VERSION ""

NS_ :

BS_:

BU_: FrontBoard BackBoard Kvaser SteeringWheel TCU GPS ACULV Bamocar PDM

BO_ 3221225472 VECTOR__INDEPENDENT_SIG_MSG: 0 Vector__XXX
 SG_ NewSignal_0021 : 0|8@1+ (1,0) [0|0] "" Vector__XXX
 SG_ NewSignal_0024 : 40|8@1+ (1,0) [0|0] "" Vector__XXX
 SG_ IsolationMonitoring : 32|8@1+ (1,0) [0|0] "" Vector__XXX
 SG_ NewSignal_0027 : 0|8@1+ (1,0) [0|0] "" Vector__XXX
 SG_ NewSignal_0029 : 8|8@1+ (1,0) [0|0] "" Vector__XXX
 SG_ Freq1 : 0|32@1- (1,0) [0|0] ""  Kvaser,SteeringWheel
 SG_ Freq2 : 32|32@1- (1,0) [0|0] ""  Kvaser,SteeringWheel

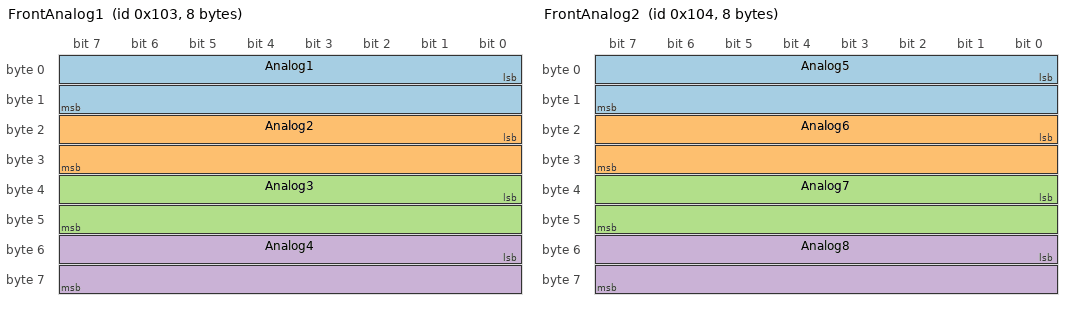
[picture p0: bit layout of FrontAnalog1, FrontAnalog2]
BO_ 259 FrontAnalog1: 8 FrontBoard
 SG_ Analog1 : 0|16@1+ (1,0) [0|0] ""  FrontBoard,Kvaser,SteeringWheel
 SG_ Analog2 : 16|16@1+ (1,0) [0|0] ""  FrontBoard,Kvaser,SteeringWheel
 SG_ Analog3 : 32|16@1+ (1,0) [0|0] ""  FrontBoard,Kvaser,SteeringWheel
 SG_ Analog4 : 48|16@1+ (1,0) [0|0] ""  FrontBoard,Kvaser,SteeringWheel

BO_ 260 FrontAnalog2: 8 FrontBoard
 SG_ Analog5 : 0|16@1+ (1,0) [0|0] ""  FrontBoard,Kvaser,SteeringWheel
 SG_ Analog6 : 16|16@1+ (1,0) [0|0] ""  FrontBoard,Kvaser,SteeringWheel
 SG_ Analog7 : 32|16@1+ (1,0) [0|0] ""  FrontBoard,Kvaser,SteeringWheel
 SG_ Analog8 : 48|16@1+ (1,0) [0|0] ""  FrontBoard,Kvaser,SteeringWheel

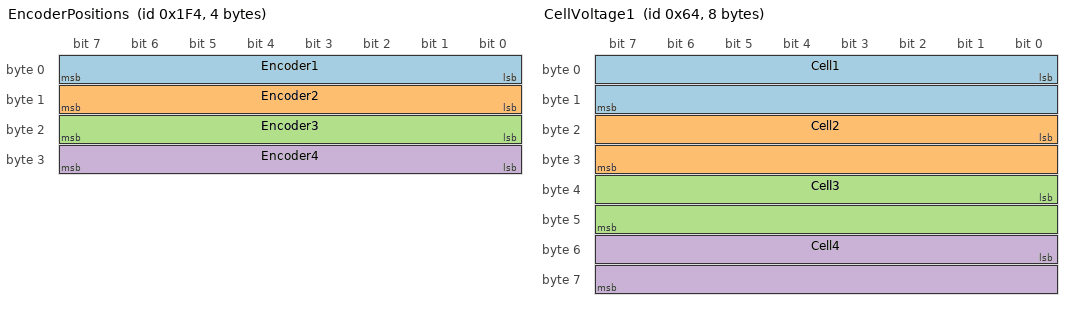
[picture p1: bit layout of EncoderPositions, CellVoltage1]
BO_ 500 EncoderPositions: 4 SteeringWheel
 SG_ Encoder1 : 0|8@1+ (1,0) [0|0] ""  Kvaser
 SG_ Encoder2 : 8|8@1+ (1,0) [0|0] ""  Kvaser
 SG_ Encoder3 : 16|8@1+ (1,0) [0|0] ""  Kvaser
 SG_ Encoder4 : 24|8@1+ (1,0) [0|0] ""  Kvaser

BO_ 1550 FrontStrainGauges1: 8 FrontBoard
 SG_ Gauge1 : 0|24@1+ (1,0) [0|0] ""  Kvaser
 SG_ Gauge2 : 24|24@1+ (1,0) [0|0] ""  Kvaser

BO_ 1551 FrontStrainGauges2: 8 FrontBoard
 SG_ Gauge3 : 0|24@1+ (1,0) [0|0] ""  Kvaser
 SG_ Gauge4 : 24|24@1+ (1,0) [0|0] ""  Kvaser

BO_ 1552 FrontStrainGauges3: 8 FrontBoard
 SG_ Gauge5 : 0|24@1+ (1,0) [0|0] ""  Kvaser
 SG_ Gauge6 : 24|24@1+ (1,0) [0|0] ""  Kvaser

BO_ 1553 FrontStrainGauges4: 8 FrontBoard
 SG_ Gauge7 : 0|24@1+ (1,0) [0|0] ""  Kvaser
 SG_ Gauge8 : 24|24@1+ (1,0) [0|0] ""  Kvaser

BO_ 1554 FrontStrainGauges5: 8 FrontBoard
 SG_ Gauge9 : 0|24@1+ (1,0) [0|0] ""  Kvaser
 SG_ Gauge10 : 24|24@1+ (1,0) [0|0] ""  Kvaser

BO_ 1555 FrontStrainGauges6: 8 FrontBoard
 SG_ Gauge11 : 0|24@1+ (1,0) [0|0] ""  Kvaser
 SG_ Gauge12 : 24|24@1+ (1,0) [0|0] ""  Kvaser

BO_ 1560 RearStrainGauges1: 8 BackBoard
 SG_ Gauge1 : 0|24@1+ (1,0) [0|0] ""  Kvaser
 SG_ Gauge2 : 24|24@1+ (1,0) [0|0] ""  Kvaser

BO_ 1561 RearStrainGauges2: 8 BackBoard
 SG_ Gauge3 : 0|24@1+ (1,0) [0|0] ""  Kvaser
 SG_ Gauge4 : 24|24@1+ (1,0) [0|0] ""  Kvaser

BO_ 1562 RearStrainGauges3: 8 BackBoard
 SG_ Gauge5 : 0|24@1+ (1,0) [0|0] ""  Kvaser
 SG_ Gauge6 : 24|24@1+ (1,0) [0|0] ""  Kvaser

BO_ 1563 RearStrainGauges4: 8 BackBoard
 SG_ Gauge7 : 0|24@1+ (1,0) [0|0] ""  Kvaser
 SG_ Gauge8 : 24|24@1+ (1,0) [0|0] ""  Kvaser

BO_ 1564 RearStrainGauges5: 8 BackBoard
 SG_ Gauge9 : 0|24@1+ (1,0) [0|0] ""  Kvaser
 SG_ Gauge10 : 24|24@1+ (1,0) [0|0] ""  Kvaser

BO_ 1565 RearStrainGauges6: 8 BackBoard
 SG_ Gauge11 : 0|24@1+ (1,0) [0|0] ""  Kvaser
 SG_ Gauge12 : 24|24@1+ (1,0) [0|0] ""  Kvaser

BO_ 80 GPSBestPos: 64 GPS
 SG_ Latitude : 0|64@1- (1,0) [0|0] ""  Kvaser,SteeringWheel
 SG_ Longitude : 64|64@1- (1,0) [0|0] ""  Kvaser,SteeringWheel
 SG_ Altitude : 128|64@1- (1,0) [0|0] ""  Kvaser,SteeringWheel
 SG_ stdLatitude : 192|64@1- (1,0) [0|0] ""  Kvaser,SteeringWheel
 SG_ stdLongitude : 256|64@1- (1,0) [0|0] ""  Kvaser,SteeringWheel
 SG_ stdAltitude : 320|64@1- (1,0) [0|0] ""  Kvaser,SteeringWheel
 SG_ gpsStatus : 384|8@1+ (1,0) [0|0] "" Vector__XXX

BO_ 513 BamocarRxData: 6 TCU
 SG_ REGID : 0|8@1- (1,0) [0|0] ""  Kvaser,SteeringWheel
 SG_ Byte1 : 8|8@1+ (1,0) [0|0] ""  Kvaser,SteeringWheel
 SG_ Byte2 : 16|8@1+ (1,0) [0|0] ""  Kvaser,SteeringWheel
 SG_ Byte3 : 24|8@1+ (1,0) [0|0] ""  Kvaser,SteeringWheel
 SG_ Byte4 : 32|8@1+ (1,0) [0|0] ""  Kvaser,SteeringWheel
 SG_ Byte5 : 40|8@1+ (1,0) [0|0] ""  Kvaser,SteeringWheel

BO_ 100 CellVoltage1: 8 ACULV
 SG_ Cell1 : 0|16@1+ (1,0) [0|0] ""  Kvaser,SteeringWheel
 SG_ Cell2 : 16|16@1+ (1,0) [0|0] ""  Kvaser,SteeringWheel
 SG_ Cell3 : 32|16@1+ (1,0) [0|0] ""  Kvaser,SteeringWheel
 SG_ Cell4 : 48|16@1+ (1,0) [0|0] ""  Kvaser,SteeringWheel

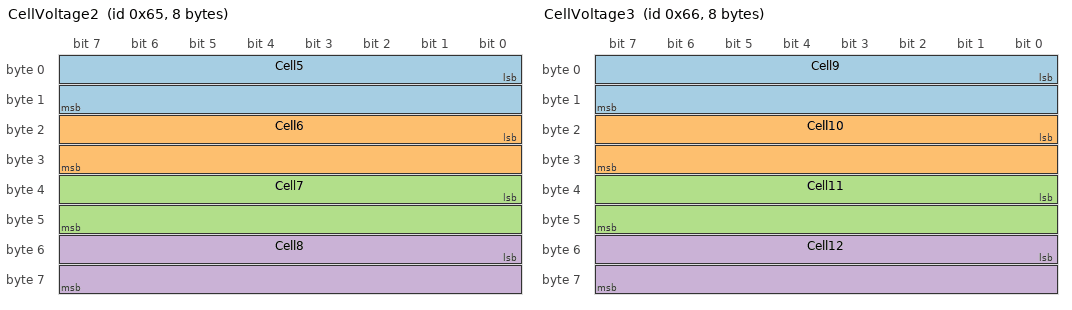
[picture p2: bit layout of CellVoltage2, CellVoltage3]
BO_ 101 CellVoltage2: 8 ACULV
 SG_ Cell5 : 0|16@1+ (1,0) [0|0] ""  Kvaser,SteeringWheel
 SG_ Cell6 : 16|16@1+ (1,0) [0|0] ""  Kvaser,SteeringWheel
 SG_ Cell7 : 32|16@1+ (1,0) [0|0] ""  Kvaser,SteeringWheel
 SG_ Cell8 : 48|16@1+ (1,0) [0|0] ""  Kvaser,SteeringWheel

BO_ 102 CellVoltage3: 8 ACULV
 SG_ Cell9 : 0|16@1+ (1,0) [0|0] ""  Kvaser,SteeringWheel
 SG_ Cell10 : 16|16@1+ (1,0) [0|0] ""  Kvaser,SteeringWheel
 SG_ Cell11 : 32|16@1+ (1,0) [0|0] ""  Kvaser,SteeringWheel
 SG_ Cell12 : 48|16@1+ (1,0) [0|0] ""  Kvaser,SteeringWheel

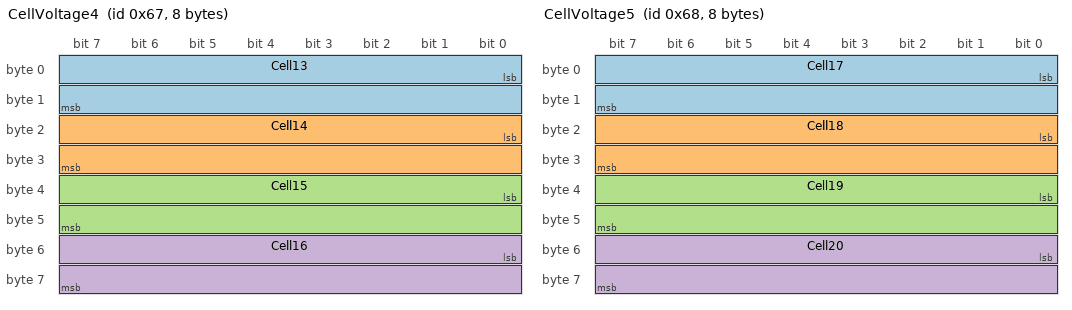
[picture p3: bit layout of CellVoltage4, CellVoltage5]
BO_ 103 CellVoltage4: 8 ACULV
 SG_ Cell13 : 0|16@1+ (1,0) [0|0] ""  Kvaser,SteeringWheel
 SG_ Cell14 : 16|16@1+ (1,0) [0|0] ""  Kvaser,SteeringWheel
 SG_ Cell15 : 32|16@1+ (1,0) [0|0] ""  Kvaser,SteeringWheel
 SG_ Cell16 : 48|16@1+ (1,0) [0|0] ""  Kvaser,SteeringWheel

BO_ 104 CellVoltage5: 8 ACULV
 SG_ Cell17 : 0|16@1+ (1,0) [0|0] ""  Kvaser,SteeringWheel
 SG_ Cell18 : 16|16@1+ (1,0) [0|0] ""  Kvaser,SteeringWheel
 SG_ Cell19 : 32|16@1+ (1,0) [0|0] ""  Kvaser,SteeringWheel
 SG_ Cell20 : 48|16@1+ (1,0) [0|0] ""  Kvaser,SteeringWheel

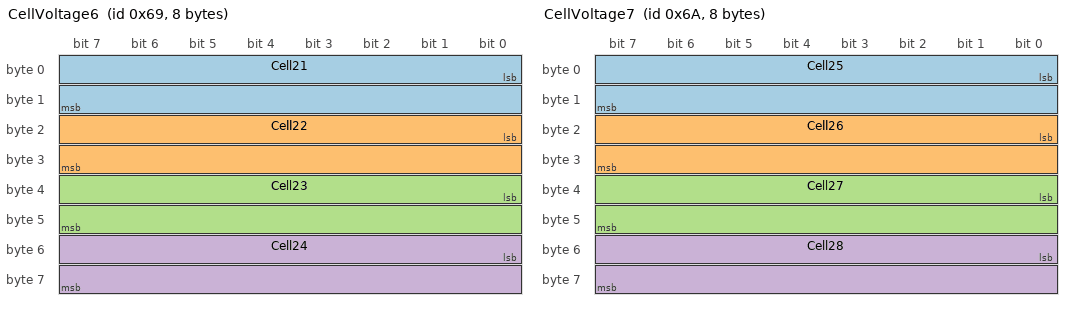
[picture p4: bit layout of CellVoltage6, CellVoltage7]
BO_ 105 CellVoltage6: 8 ACULV
 SG_ Cell21 : 0|16@1+ (1,0) [0|0] ""  Kvaser,SteeringWheel
 SG_ Cell22 : 16|16@1+ (1,0) [0|0] ""  Kvaser,SteeringWheel
 SG_ Cell23 : 32|16@1+ (1,0) [0|0] ""  Kvaser,SteeringWheel
 SG_ Cell24 : 48|16@1+ (1,0) [0|0] ""  Kvaser,SteeringWheel

BO_ 106 CellVoltage7: 8 ACULV
 SG_ Cell25 : 0|16@1+ (1,0) [0|0] ""  Kvaser,SteeringWheel
 SG_ Cell26 : 16|16@1+ (1,0) [0|0] ""  Kvaser,SteeringWheel
 SG_ Cell27 : 32|16@1+ (1,0) [0|0] ""  Kvaser,SteeringWheel
 SG_ Cell28 : 48|16@1+ (1,0) [0|0] ""  Kvaser,SteeringWheel

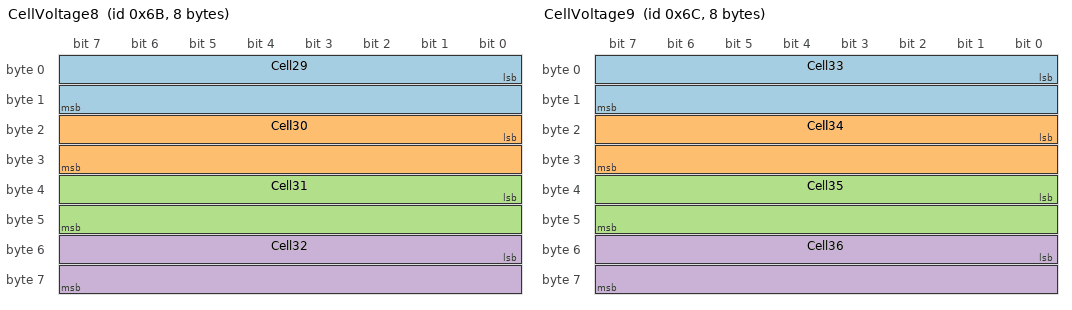
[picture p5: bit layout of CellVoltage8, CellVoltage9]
BO_ 107 CellVoltage8: 8 ACULV
 SG_ Cell29 : 0|16@1+ (1,0) [0|0] ""  Kvaser,SteeringWheel
 SG_ Cell30 : 16|16@1+ (1,0) [0|0] ""  Kvaser,SteeringWheel
 SG_ Cell31 : 32|16@1+ (1,0) [0|0] ""  Kvaser,SteeringWheel
 SG_ Cell32 : 48|16@1+ (1,0) [0|0] ""  Kvaser,SteeringWheel

BO_ 108 CellVoltage9: 8 ACULV
 SG_ Cell33 : 0|16@1+ (1,0) [0|0] ""  Kvaser,SteeringWheel
 SG_ Cell34 : 16|16@1+ (1,0) [0|0] ""  Kvaser,SteeringWheel
 SG_ Cell35 : 32|16@1+ (1,0) [0|0] ""  Kvaser,SteeringWheel
 SG_ Cell36 : 48|16@1+ (1,0) [0|0] ""  Kvaser,SteeringWheel

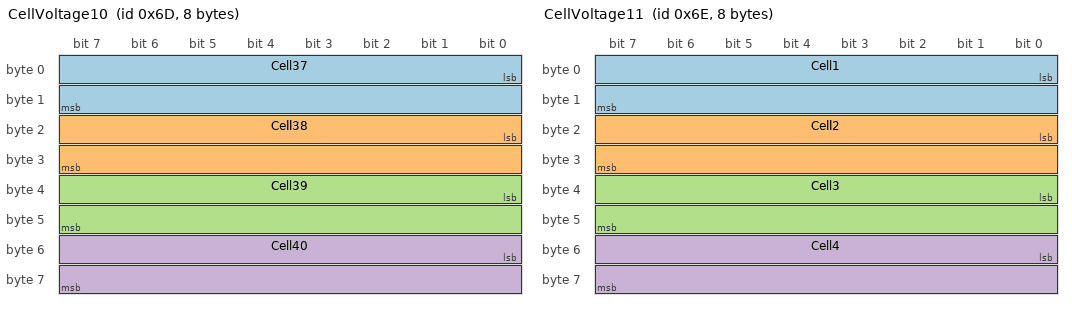
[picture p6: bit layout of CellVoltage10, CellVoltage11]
BO_ 109 CellVoltage10: 8 ACULV
 SG_ Cell37 : 0|16@1+ (1,0) [0|0] ""  Kvaser,SteeringWheel
 SG_ Cell38 : 16|16@1+ (1,0) [0|0] ""  Kvaser,SteeringWheel
 SG_ Cell39 : 32|16@1+ (1,0) [0|0] ""  Kvaser,SteeringWheel
 SG_ Cell40 : 48|16@1+ (1,0) [0|0] ""  Kvaser,SteeringWheel

BO_ 110 CellVoltage11: 8 ACULV
 SG_ Cell1 : 0|16@1+ (1,0) [0|0] ""  Kvaser,SteeringWheel
 SG_ Cell2 : 16|16@1+ (1,0) [0|0] ""  Kvaser,SteeringWheel
 SG_ Cell3 : 32|16@1+ (1,0) [0|0] ""  Kvaser,SteeringWheel
 SG_ Cell4 : 48|16@1+ (1,0) [0|0] ""  Kvaser,SteeringWheel

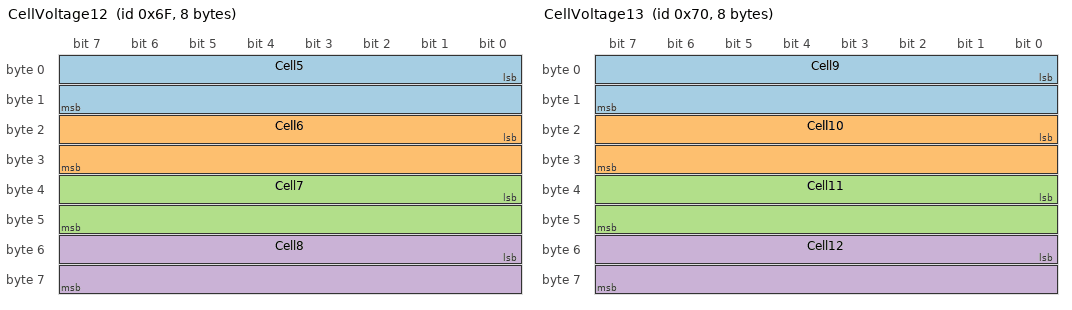
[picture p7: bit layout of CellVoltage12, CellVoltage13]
BO_ 111 CellVoltage12: 8 ACULV
 SG_ Cell5 : 0|16@1+ (1,0) [0|0] ""  Kvaser,SteeringWheel
 SG_ Cell6 : 16|16@1+ (1,0) [0|0] ""  Kvaser,SteeringWheel
 SG_ Cell7 : 32|16@1+ (1,0) [0|0] ""  Kvaser,SteeringWheel
 SG_ Cell8 : 48|16@1+ (1,0) [0|0] ""  Kvaser,SteeringWheel

BO_ 112 CellVoltage13: 8 ACULV
 SG_ Cell9 : 0|16@1+ (1,0) [0|0] ""  Kvaser,SteeringWheel
 SG_ Cell10 : 16|16@1+ (1,0) [0|0] ""  Kvaser,SteeringWheel
 SG_ Cell11 : 32|16@1+ (1,0) [0|0] ""  Kvaser,SteeringWheel
 SG_ Cell12 : 48|16@1+ (1,0) [0|0] ""  Kvaser,SteeringWheel

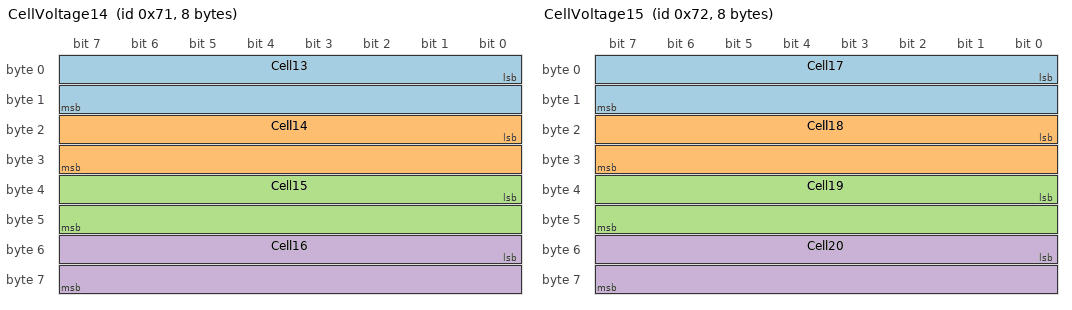
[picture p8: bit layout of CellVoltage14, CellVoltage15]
BO_ 113 CellVoltage14: 8 ACULV
 SG_ Cell13 : 0|16@1+ (1,0) [0|0] ""  Kvaser,SteeringWheel
 SG_ Cell14 : 16|16@1+ (1,0) [0|0] ""  Kvaser,SteeringWheel
 SG_ Cell15 : 32|16@1+ (1,0) [0|0] ""  Kvaser,SteeringWheel
 SG_ Cell16 : 48|16@1+ (1,0) [0|0] ""  Kvaser,SteeringWheel

BO_ 114 CellVoltage15: 8 ACULV
 SG_ Cell17 : 0|16@1+ (1,0) [0|0] ""  Kvaser,SteeringWheel
 SG_ Cell18 : 16|16@1+ (1,0) [0|0] ""  Kvaser,SteeringWheel
 SG_ Cell19 : 32|16@1+ (1,0) [0|0] ""  Kvaser,SteeringWheel
 SG_ Cell20 : 48|16@1+ (1,0) [0|0] ""  Kvaser,SteeringWheel

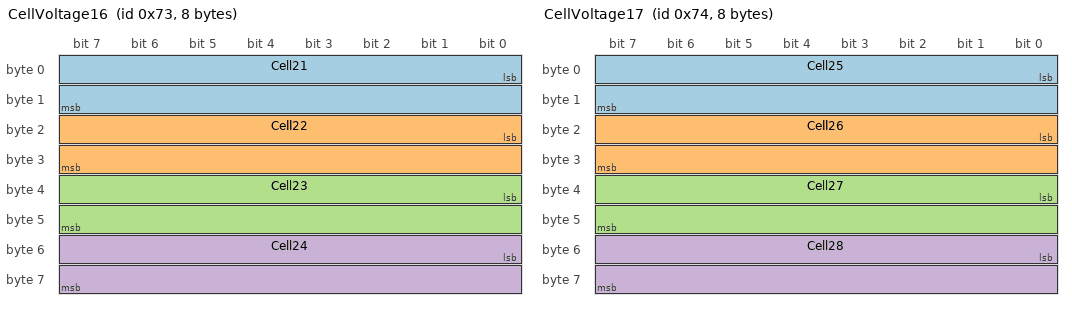
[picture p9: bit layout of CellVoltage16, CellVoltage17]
BO_ 115 CellVoltage16: 8 ACULV
 SG_ Cell21 : 0|16@1+ (1,0) [0|0] ""  Kvaser,SteeringWheel
 SG_ Cell22 : 16|16@1+ (1,0) [0|0] ""  Kvaser,SteeringWheel
 SG_ Cell23 : 32|16@1+ (1,0) [0|0] ""  Kvaser,SteeringWheel
 SG_ Cell24 : 48|16@1+ (1,0) [0|0] ""  Kvaser,SteeringWheel

BO_ 116 CellVoltage17: 8 ACULV
 SG_ Cell25 : 0|16@1+ (1,0) [0|0] ""  Kvaser,SteeringWheel
 SG_ Cell26 : 16|16@1+ (1,0) [0|0] ""  Kvaser,SteeringWheel
 SG_ Cell27 : 32|16@1+ (1,0) [0|0] ""  Kvaser,SteeringWheel
 SG_ Cell28 : 48|16@1+ (1,0) [0|0] ""  Kvaser,SteeringWheel

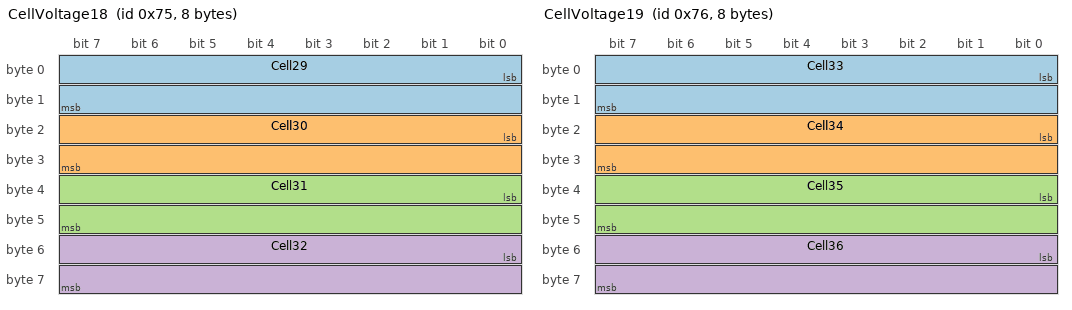
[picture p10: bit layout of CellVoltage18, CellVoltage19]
BO_ 117 CellVoltage18: 8 ACULV
 SG_ Cell29 : 0|16@1+ (1,0) [0|0] ""  Kvaser,SteeringWheel
 SG_ Cell30 : 16|16@1+ (1,0) [0|0] ""  Kvaser,SteeringWheel
 SG_ Cell31 : 32|16@1+ (1,0) [0|0] ""  Kvaser,SteeringWheel
 SG_ Cell32 : 48|16@1+ (1,0) [0|0] ""  Kvaser,SteeringWheel

BO_ 118 CellVoltage19: 8 ACULV
 SG_ Cell33 : 0|16@1+ (1,0) [0|0] ""  Kvaser,SteeringWheel
 SG_ Cell34 : 16|16@1+ (1,0) [0|0] ""  Kvaser,SteeringWheel
 SG_ Cell35 : 32|16@1+ (1,0) [0|0] ""  Kvaser,SteeringWheel
 SG_ Cell36 : 48|16@1+ (1,0) [0|0] ""  Kvaser,SteeringWheel

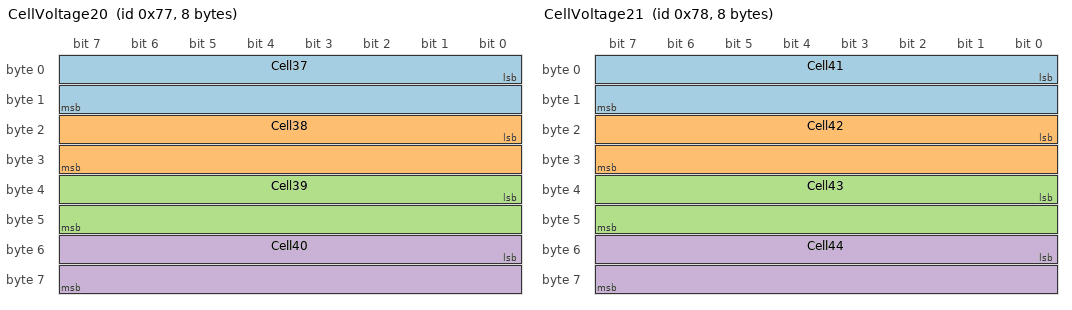
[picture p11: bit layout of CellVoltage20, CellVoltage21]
BO_ 119 CellVoltage20: 8 ACULV
 SG_ Cell37 : 0|16@1+ (1,0) [0|0] ""  Kvaser,SteeringWheel
 SG_ Cell38 : 16|16@1+ (1,0) [0|0] ""  Kvaser,SteeringWheel
 SG_ Cell39 : 32|16@1+ (1,0) [0|0] ""  Kvaser,SteeringWheel
 SG_ Cell40 : 48|16@1+ (1,0) [0|0] ""  Kvaser,SteeringWheel

BO_ 120 CellVoltage21: 8 ACULV
 SG_ Cell41 : 0|16@1+ (1,0) [0|0] ""  Kvaser,SteeringWheel
 SG_ Cell42 : 16|16@1+ (1,0) [0|0] ""  Kvaser,SteeringWheel
 SG_ Cell43 : 32|16@1+ (1,0) [0|0] ""  Kvaser,SteeringWheel
 SG_ Cell44 : 48|16@1+ (1,0) [0|0] ""  Kvaser,SteeringWheel

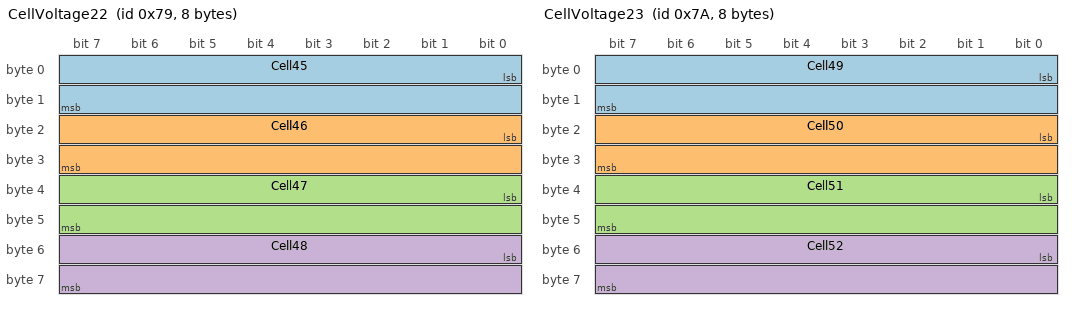
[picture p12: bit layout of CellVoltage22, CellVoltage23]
BO_ 121 CellVoltage22: 8 ACULV
 SG_ Cell45 : 0|16@1+ (1,0) [0|0] ""  Kvaser,SteeringWheel
 SG_ Cell46 : 16|16@1+ (1,0) [0|0] ""  Kvaser,SteeringWheel
 SG_ Cell47 : 32|16@1+ (1,0) [0|0] ""  Kvaser,SteeringWheel
 SG_ Cell48 : 48|16@1+ (1,0) [0|0] ""  Kvaser,SteeringWheel

BO_ 122 CellVoltage23: 8 ACULV
 SG_ Cell49 : 0|16@1+ (1,0) [0|0] ""  Kvaser,SteeringWheel
 SG_ Cell50 : 16|16@1+ (1,0) [0|0] ""  Kvaser,SteeringWheel
 SG_ Cell51 : 32|16@1+ (1,0) [0|0] ""  Kvaser,SteeringWheel
 SG_ Cell52 : 48|16@1+ (1,0) [0|0] ""  Kvaser,SteeringWheel

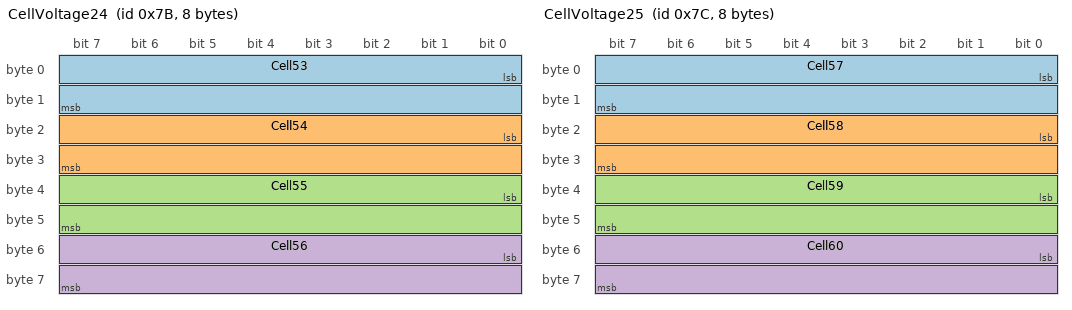
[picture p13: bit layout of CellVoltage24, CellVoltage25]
BO_ 123 CellVoltage24: 8 ACULV
 SG_ Cell53 : 0|16@1+ (1,0) [0|0] ""  Kvaser,SteeringWheel
 SG_ Cell54 : 16|16@1+ (1,0) [0|0] ""  Kvaser,SteeringWheel
 SG_ Cell55 : 32|16@1+ (1,0) [0|0] ""  Kvaser,SteeringWheel
 SG_ Cell56 : 48|16@1+ (1,0) [0|0] ""  Kvaser,SteeringWheel

BO_ 124 CellVoltage25: 8 ACULV
 SG_ Cell57 : 0|16@1+ (1,0) [0|0] ""  Kvaser,SteeringWheel
 SG_ Cell58 : 16|16@1+ (1,0) [0|0] ""  Kvaser,SteeringWheel
 SG_ Cell59 : 32|16@1+ (1,0) [0|0] ""  Kvaser,SteeringWheel
 SG_ Cell60 : 48|16@1+ (1,0) [0|0] ""  Kvaser,SteeringWheel

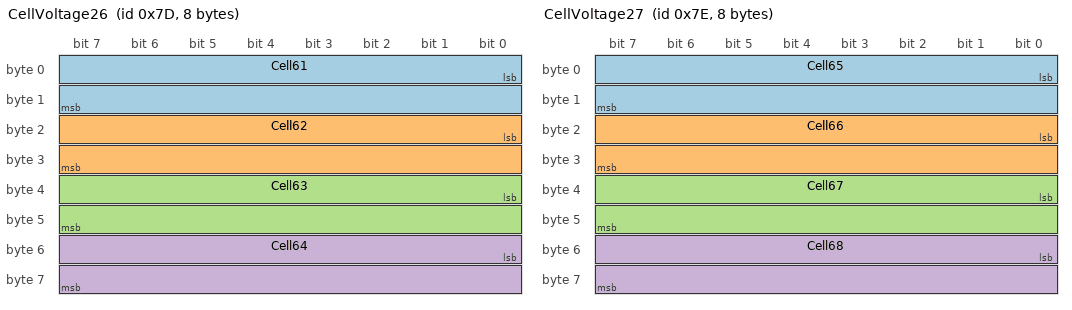
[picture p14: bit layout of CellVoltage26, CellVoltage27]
BO_ 125 CellVoltage26: 8 ACULV
 SG_ Cell61 : 0|16@1+ (1,0) [0|0] ""  Kvaser,SteeringWheel
 SG_ Cell62 : 16|16@1+ (1,0) [0|0] ""  Kvaser,SteeringWheel
 SG_ Cell63 : 32|16@1+ (1,0) [0|0] ""  Kvaser,SteeringWheel
 SG_ Cell64 : 48|16@1+ (1,0) [0|0] ""  Kvaser,SteeringWheel

BO_ 126 CellVoltage27: 8 ACULV
 SG_ Cell65 : 0|16@1+ (1,0) [0|0] ""  Kvaser,SteeringWheel
 SG_ Cell66 : 16|16@1+ (1,0) [0|0] ""  Kvaser,SteeringWheel
 SG_ Cell67 : 32|16@1+ (1,0) [0|0] ""  Kvaser,SteeringWheel
 SG_ Cell68 : 48|16@1+ (1,0) [0|0] ""  Kvaser,SteeringWheel

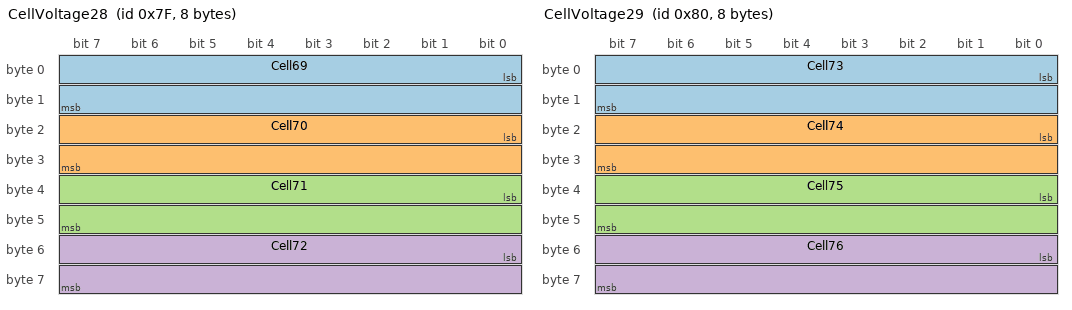
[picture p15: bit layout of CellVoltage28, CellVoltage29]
BO_ 127 CellVoltage28: 8 ACULV
 SG_ Cell69 : 0|16@1+ (1,0) [0|0] ""  Kvaser,SteeringWheel
 SG_ Cell70 : 16|16@1+ (1,0) [0|0] ""  Kvaser,SteeringWheel
 SG_ Cell71 : 32|16@1+ (1,0) [0|0] ""  Kvaser,SteeringWheel
 SG_ Cell72 : 48|16@1+ (1,0) [0|0] ""  Kvaser,SteeringWheel

BO_ 128 CellVoltage29: 8 ACULV
 SG_ Cell73 : 0|16@1+ (1,0) [0|0] ""  Kvaser,SteeringWheel
 SG_ Cell74 : 16|16@1+ (1,0) [0|0] ""  Kvaser,SteeringWheel
 SG_ Cell75 : 32|16@1+ (1,0) [0|0] ""  Kvaser,SteeringWheel
 SG_ Cell76 : 48|16@1+ (1,0) [0|0] ""  Kvaser,SteeringWheel

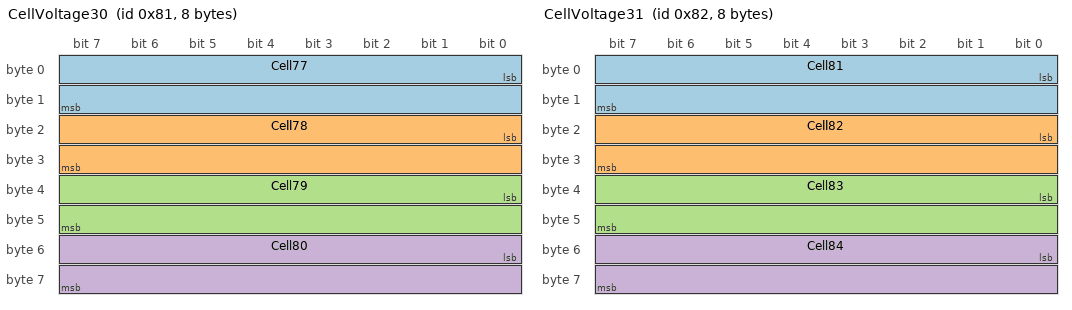
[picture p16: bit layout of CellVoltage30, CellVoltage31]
BO_ 129 CellVoltage30: 8 ACULV
 SG_ Cell77 : 0|16@1+ (1,0) [0|0] ""  Kvaser,SteeringWheel
 SG_ Cell78 : 16|16@1+ (1,0) [0|0] ""  Kvaser,SteeringWheel
 SG_ Cell79 : 32|16@1+ (1,0) [0|0] ""  Kvaser,SteeringWheel
 SG_ Cell80 : 48|16@1+ (1,0) [0|0] ""  Kvaser,SteeringWheel

BO_ 130 CellVoltage31: 8 ACULV
 SG_ Cell81 : 0|16@1+ (1,0) [0|0] ""  Kvaser,SteeringWheel
 SG_ Cell82 : 16|16@1+ (1,0) [0|0] ""  Kvaser,SteeringWheel
 SG_ Cell83 : 32|16@1+ (1,0) [0|0] ""  Kvaser,SteeringWheel
 SG_ Cell84 : 48|16@1+ (1,0) [0|0] ""  Kvaser,SteeringWheel

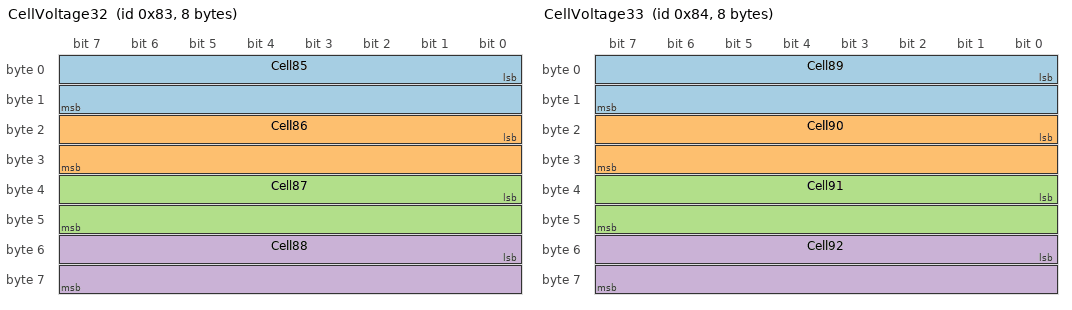
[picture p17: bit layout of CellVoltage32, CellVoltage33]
BO_ 131 CellVoltage32: 8 ACULV
 SG_ Cell85 : 0|16@1+ (1,0) [0|0] ""  Kvaser,SteeringWheel
 SG_ Cell86 : 16|16@1+ (1,0) [0|0] ""  Kvaser,SteeringWheel
 SG_ Cell87 : 32|16@1+ (1,0) [0|0] ""  Kvaser,SteeringWheel
 SG_ Cell88 : 48|16@1+ (1,0) [0|0] ""  Kvaser,SteeringWheel

BO_ 132 CellVoltage33: 8 ACULV
 SG_ Cell89 : 0|16@1+ (1,0) [0|0] ""  Kvaser,SteeringWheel
 SG_ Cell90 : 16|16@1+ (1,0) [0|0] ""  Kvaser,SteeringWheel
 SG_ Cell91 : 32|16@1+ (1,0) [0|0] ""  Kvaser,SteeringWheel
 SG_ Cell92 : 48|16@1+ (1,0) [0|0] ""  Kvaser,SteeringWheel

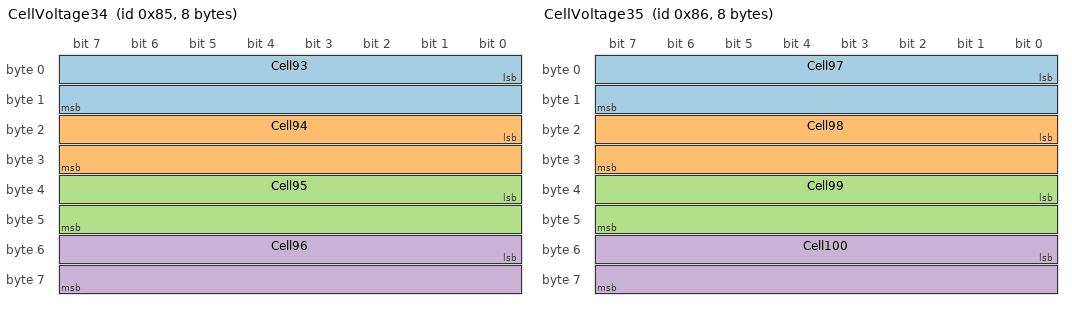
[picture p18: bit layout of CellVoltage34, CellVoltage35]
BO_ 133 CellVoltage34: 8 ACULV
 SG_ Cell93 : 0|16@1+ (1,0) [0|0] ""  Kvaser,SteeringWheel
 SG_ Cell94 : 16|16@1+ (1,0) [0|0] ""  Kvaser,SteeringWheel
 SG_ Cell95 : 32|16@1+ (1,0) [0|0] ""  Kvaser,SteeringWheel
 SG_ Cell96 : 48|16@1+ (1,0) [0|0] ""  Kvaser,SteeringWheel

BO_ 134 CellVoltage35: 8 ACULV
 SG_ Cell97 : 0|16@1+ (1,0) [0|0] ""  Kvaser,SteeringWheel
 SG_ Cell98 : 16|16@1+ (1,0) [0|0] ""  Kvaser,SteeringWheel
 SG_ Cell99 : 32|16@1+ (1,0) [0|0] ""  Kvaser,SteeringWheel
 SG_ Cell100 : 48|16@1+ (1,0) [0|0] ""  Kvaser,SteeringWheel

BO_ 135 CellVoltage36: 8 ACULV
 SG_ Cell101 : 0|16@1+ (1,0) [0|0] ""  Kvaser,SteeringWheel
 SG_ Cell102 : 16|16@1+ (1,0) [0|0] ""  Kvaser,SteeringWheel
 SG_ Cell103 : 32|16@1+ (1,0) [0|0] ""  Kvaser,SteeringWheel
 SG_ Cell104 : 48|16@1+ (1,0) [0|0] ""  Kvaser,SteeringWheel

BO_ 136 CellVoltage37: 8 ACULV
 SG_ Cell105 : 0|16@1+ (1,0) [0|0] ""  Kvaser,SteeringWheel
 SG_ Cell106 : 16|16@1+ (1,0) [0|0] ""  Kvaser,SteeringWheel
 SG_ Cell107 : 32|16@1+ (1,0) [0|0] ""  Kvaser,SteeringWheel
 SG_ Cell108 : 48|16@1+ (1,0) [0|0] ""  Kvaser,SteeringWheel

BO_ 137 CellVoltage38: 8 ACULV
 SG_ Cell109 : 0|16@1+ (1,0) [0|0] ""  Kvaser,SteeringWheel
 SG_ Cell110 : 16|16@1+ (1,0) [0|0] ""  Kvaser,SteeringWheel
 SG_ Cell111 : 32|16@1+ (1,0) [0|0] ""  Kvaser,SteeringWheel
 SG_ Cell112 : 48|16@1+ (1,0) [0|0] ""  Kvaser,SteeringWheel

BO_ 138 CellVoltage39: 8 ACULV
 SG_ Cell113 : 0|16@1+ (1,0) [0|0] ""  Kvaser,SteeringWheel
 SG_ Cell114 : 16|16@1+ (1,0) [0|0] ""  Kvaser,SteeringWheel
 SG_ Cell115 : 32|16@1+ (1,0) [0|0] ""  Kvaser,SteeringWheel
 SG_ Cell116 : 48|16@1+ (1,0) [0|0] ""  Kvaser,SteeringWheel

BO_ 139 CellVoltage40: 8 ACULV
 SG_ Cell117 : 0|16@1+ (1,0) [0|0] ""  Kvaser,SteeringWheel
 SG_ Cell118 : 16|16@1+ (1,0) [0|0] ""  Kvaser,SteeringWheel
 SG_ Cell119 : 32|16@1+ (1,0) [0|0] ""  Kvaser,SteeringWheel
 SG_ Cell120 : 48|16@1+ (1,0) [0|0] ""  Kvaser,SteeringWheel

BO_ 140 CellVoltage41: 8 ACULV
 SG_ Cell121 : 0|16@1+ (1,0) [0|0] ""  Kvaser,SteeringWheel
 SG_ Cell122 : 16|16@1+ (1,0) [0|0] ""  Kvaser,SteeringWheel
 SG_ Cell123 : 32|16@1+ (1,0) [0|0] ""  Kvaser,SteeringWheel
 SG_ Cell124 : 48|16@1+ (1,0) [0|0] ""  Kvaser,SteeringWheel

BO_ 141 CellVoltage42: 8 ACULV
 SG_ Cell125 : 0|16@1+ (1,0) [0|0] ""  Kvaser,SteeringWheel
 SG_ Cell126 : 16|16@1+ (1,0) [0|0] ""  Kvaser,SteeringWheel
 SG_ Cell127 : 32|16@1+ (1,0) [0|0] ""  Kvaser,SteeringWheel
 SG_ Cell128 : 48|16@1+ (1,0) [0|0] ""  Kvaser,SteeringWheel

BO_ 142 CellVoltage43: 8 ACULV
 SG_ Cell129 : 0|16@1+ (1,0) [0|0] ""  Kvaser,SteeringWheel
 SG_ Cell130 : 16|16@1+ (1,0) [0|0] ""  Kvaser,SteeringWheel
 SG_ Cell131 : 32|16@1+ (1,0) [0|0] ""  Kvaser,SteeringWheel
 SG_ Cell132 : 48|16@1+ (1,0) [0|0] ""  Kvaser,SteeringWheel

BO_ 200 Thermistor1: 8 ACULV
 SG_ Therm1 : 0|16@1+ (1,0) [0|0] ""  Kvaser,SteeringWheel
 SG_ Therm2 : 16|16@1+ (1,0) [0|0] ""  Kvaser,SteeringWheel
 SG_ Therm3 : 32|16@1+ (1,0) [0|0] ""  Kvaser,SteeringWheel
 SG_ Therm4 : 48|16@1+ (1,0) [0|0] ""  Kvaser,SteeringWheel

BO_ 201 Thermistor2: 8 ACULV
 SG_ Therm5 : 0|16@1+ (1,0) [0|0] ""  Kvaser,SteeringWheel
 SG_ Therm6 : 16|16@1+ (1,0) [0|0] ""  Kvaser,SteeringWheel
 SG_ Therm7 : 32|16@1+ (1,0) [0|0] ""  Kvaser,SteeringWheel
 SG_ Therm8 : 48|16@1+ (1,0) [0|0] ""  Kvaser,SteeringWheel

BO_ 202 Thermistor3: 8 ACULV
 SG_ Therm9 : 0|16@1+ (1,0) [0|0] ""  Kvaser,SteeringWheel
 SG_ Therm10 : 16|16@1+ (1,0) [0|0] ""  Kvaser,SteeringWheel
 SG_ Therm11 : 32|16@1+ (1,0) [0|0] ""  Kvaser,SteeringWheel
 SG_ Therm12 : 48|16@1+ (1,0) [0|0] ""  Kvaser,SteeringWheel

BO_ 203 Thermistor4: 8 ACULV
 SG_ Therm13 : 0|16@1+ (1,0) [0|0] ""  Kvaser,SteeringWheel
 SG_ Therm14 : 16|16@1+ (1,0) [0|0] ""  Kvaser,SteeringWheel
 SG_ Therm15 : 32|16@1+ (1,0) [0|0] ""  Kvaser,SteeringWheel
 SG_ Therm16 : 48|16@1+ (1,0) [0|0] ""  Kvaser,SteeringWheel

BO_ 204 Thermistor5: 8 ACULV
 SG_ Therm17 : 0|16@1+ (1,0) [0|0] ""  Kvaser,SteeringWheel
 SG_ Therm18 : 16|16@1+ (1,0) [0|0] ""  Kvaser,SteeringWheel
 SG_ Therm19 : 32|16@1+ (1,0) [0|0] ""  Kvaser,SteeringWheel
 SG_ Therm20 : 48|16@1+ (1,0) [0|0] ""  Kvaser,SteeringWheel

BO_ 205 Thermistor6: 8 ACULV
 SG_ Therm21 : 0|16@1+ (1,0) [0|0] ""  Kvaser,SteeringWheel
 SG_ Therm22 : 16|16@1+ (1,0) [0|0] ""  Kvaser,SteeringWheel
 SG_ Therm23 : 32|16@1+ (1,0) [0|0] ""  Kvaser,SteeringWheel
 SG_ Therm24 : 48|16@1+ (1,0) [0|0] ""  Kvaser,SteeringWheel

BO_ 206 Thermistor7: 8 ACULV
 SG_ Therm25 : 0|16@1+ (1,0) [0|0] ""  Kvaser,SteeringWheel
 SG_ Therm26 : 16|16@1+ (1,0) [0|0] ""  Kvaser,SteeringWheel
 SG_ Therm27 : 32|16@1+ (1,0) [0|0] ""  Kvaser,SteeringWheel
 SG_ Therm28 : 48|16@1+ (1,0) [0|0] ""  Kvaser,SteeringWheel

BO_ 207 Thermistor8: 8 ACULV
 SG_ Therm29 : 0|16@1+ (1,0) [0|0] ""  Kvaser,SteeringWheel
 SG_ Therm30 : 16|16@1+ (1,0) [0|0] ""  Kvaser,SteeringWheel
 SG_ Therm31 : 32|16@1+ (1,0) [0|0] ""  Kvaser,SteeringWheel
 SG_ Therm32 : 48|16@1+ (1,0) [0|0] ""  Kvaser,SteeringWheel

BO_ 208 Thermistor9: 8 ACULV
 SG_ Therm33 : 0|16@1+ (1,0) [0|0] ""  Kvaser,SteeringWheel
 SG_ Therm34 : 16|16@1+ (1,0) [0|0] ""  Kvaser,SteeringWheel
 SG_ Therm35 : 32|16@1+ (1,0) [0|0] ""  Kvaser,SteeringWheel
 SG_ Therm36 : 48|16@1+ (1,0) [0|0] ""  Kvaser,SteeringWheel

BO_ 209 Thermistor10: 8 ACULV
 SG_ Therm37 : 0|16@1+ (1,0) [0|0] ""  Kvaser,SteeringWheel
 SG_ Therm38 : 16|16@1+ (1,0) [0|0] ""  Kvaser,SteeringWheel
 SG_ Therm39 : 32|16@1+ (1,0) [0|0] ""  Kvaser,SteeringWheel
 SG_ Therm40 : 48|16@1+ (1,0) [0|0] ""  Kvaser,SteeringWheel

BO_ 210 Thermistor11: 8 ACULV
 SG_ Therm41 : 0|16@1+ (1,0) [0|0] ""  Kvaser,SteeringWheel
 SG_ Therm42 : 16|16@1+ (1,0) [0|0] ""  Kvaser,SteeringWheel
 SG_ Therm43 : 32|16@1+ (1,0) [0|0] ""  Kvaser,SteeringWheel
 SG_ Therm44 : 48|16@1+ (1,0) [0|0] ""  Kvaser,SteeringWheel

BO_ 211 Thermistor12: 8 ACULV
 SG_ Therm45 : 0|16@1+ (1,0) [0|0] ""  Kvaser,SteeringWheel
 SG_ Therm46 : 16|16@1+ (1,0) [0|0] ""  Kvaser,SteeringWheel
 SG_ Therm47 : 32|16@1+ (1,0) [0|0] ""  Kvaser,SteeringWheel
 SG_ Therm48 : 48|16@1+ (1,0) [0|0] ""  Kvaser,SteeringWheel

BO_ 212 Thermistor13: 8 ACULV
 SG_ Therm49 : 0|16@1+ (1,0) [0|0] ""  Kvaser,SteeringWheel
 SG_ Therm50 : 16|16@1+ (1,0) [0|0] ""  Kvaser,SteeringWheel
 SG_ Therm51 : 32|16@1+ (1,0) [0|0] ""  Kvaser,SteeringWheel
 SG_ Therm52 : 48|16@1+ (1,0) [0|0] ""  Kvaser,SteeringWheel

BO_ 213 Thermistor14: 8 ACULV
 SG_ Therm53 : 0|16@1+ (1,0) [0|0] ""  Kvaser,SteeringWheel
 SG_ Therm54 : 16|16@1+ (1,0) [0|0] ""  Kvaser,SteeringWheel
 SG_ Therm55 : 32|16@1+ (1,0) [0|0] ""  Kvaser,SteeringWheel
 SG_ Therm56 : 48|16@1+ (1,0) [0|0] ""  Kvaser,SteeringWheel

BO_ 214 Thermistor15: 8 ACULV
 SG_ Therm57 : 0|16@1+ (1,0) [0|0] ""  Kvaser,SteeringWheel
 SG_ Therm58 : 16|16@1+ (1,0) [0|0] ""  Kvaser,SteeringWheel
 SG_ Therm59 : 32|16@1+ (1,0) [0|0] ""  Kvaser,SteeringWheel
 SG_ Therm60 : 48|16@1+ (1,0) [0|0] ""  Kvaser,SteeringWheel

BO_ 215 Thermistor16: 8 ACULV
 SG_ Therm61 : 0|16@1+ (1,0) [0|0] ""  Kvaser,SteeringWheel
 SG_ Therm62 : 16|16@1+ (1,0) [0|0] ""  Kvaser,SteeringWheel
 SG_ Therm63 : 32|16@1+ (1,0) [0|0] ""  Kvaser,SteeringWheel
 SG_ Therm64 : 48|16@1+ (1,0) [0|0] ""  Kvaser,SteeringWheel

BO_ 216 Thermistor17: 8 ACULV
 SG_ Therm65 : 0|16@1+ (1,0) [0|0] ""  Kvaser,SteeringWheel
 SG_ Therm66 : 16|16@1+ (1,0) [0|0] ""  Kvaser,SteeringWheel
 SG_ Therm67 : 32|16@1+ (1,0) [0|0] ""  Kvaser,SteeringWheel
 SG_ Therm68 : 48|16@1+ (1,0) [0|0] ""  Kvaser,SteeringWheel

BO_ 217 Thermistor18: 8 ACULV
 SG_ Therm69 : 0|16@1+ (1,0) [0|0] ""  Kvaser,SteeringWheel
 SG_ Therm70 : 16|16@1+ (1,0) [0|0] ""  Kvaser,SteeringWheel
 SG_ Therm71 : 32|16@1+ (1,0) [0|0] ""  Kvaser,SteeringWheel
 SG_ Therm72 : 48|16@1+ (1,0) [0|0] ""  Kvaser,SteeringWheel

BO_ 218 Thermistor19: 8 ACULV
 SG_ Therm73 : 0|16@1+ (1,0) [0|0] ""  Kvaser,SteeringWheel
 SG_ Therm74 : 16|16@1+ (1,0) [0|0] ""  Kvaser,SteeringWheel
 SG_ Therm75 : 32|16@1+ (1,0) [0|0] ""  Kvaser,SteeringWheel
 SG_ Therm76 : 48|16@1+ (1,0) [0|0] ""  Kvaser,SteeringWheel

BO_ 219 Thermistor20: 8 ACULV
 SG_ Therm77 : 0|16@1+ (1,0) [0|0] ""  Kvaser,SteeringWheel
 SG_ Therm78 : 16|16@1+ (1,0) [0|0] ""  Kvaser,SteeringWheel
 SG_ Therm79 : 32|16@1+ (1,0) [0|0] ""  Kvaser,SteeringWheel
 SG_ Therm80 : 48|16@1+ (1,0) [0|0] ""  Kvaser,SteeringWheel

BO_ 220 Thermistor21: 8 ACULV
 SG_ Therm81 : 0|16@1+ (1,0) [0|0] ""  Kvaser,SteeringWheel
 SG_ Therm82 : 16|16@1+ (1,0) [0|0] ""  Kvaser,SteeringWheel
 SG_ Therm83 : 32|16@1+ (1,0) [0|0] ""  Kvaser,SteeringWheel
 SG_ Therm84 : 48|16@1+ (1,0) [0|0] ""  Kvaser,SteeringWheel

BO_ 221 Thermistor22: 8 ACULV
 SG_ Therm85 : 0|16@1+ (1,0) [0|0] ""  Kvaser,SteeringWheel
 SG_ Therm86 : 16|16@1+ (1,0) [0|0] ""  Kvaser,SteeringWheel
 SG_ Therm87 : 32|16@1+ (1,0) [0|0] ""  Kvaser,SteeringWheel
 SG_ Therm88 : 48|16@1+ (1,0) [0|0] ""  Kvaser,SteeringWheel

BO_ 222 Thermistor23: 8 ACULV
 SG_ Therm89 : 0|16@1+ (1,0) [0|0] ""  Kvaser,SteeringWheel
 SG_ Therm90 : 16|16@1+ (1,0) [0|0] ""  Kvaser,SteeringWheel
 SG_ Therm91 : 32|16@1+ (1,0) [0|0] ""  Kvaser,SteeringWheel
 SG_ Therm92 : 48|16@1+ (1,0) [0|0] ""  Kvaser,SteeringWheel

BO_ 223 Thermistor24: 8 ACULV
 SG_ Therm93 : 0|16@1+ (1,0) [0|0] ""  Kvaser,SteeringWheel
 SG_ Therm94 : 16|16@1+ (1,0) [0|0] ""  Kvaser,SteeringWheel
 SG_ Therm95 : 32|16@1+ (1,0) [0|0] ""  Kvaser,SteeringWheel
 SG_ Therm96 : 48|16@1+ (1,0) [0|0] ""  Kvaser,SteeringWheel

BO_ 224 Thermistor25: 8 ACULV
 SG_ Therm97 : 0|16@1+ (1,0) [0|0] ""  Kvaser,SteeringWheel
 SG_ Therm98 : 16|16@1+ (1,0) [0|0] ""  Kvaser,SteeringWheel
 SG_ Therm99 : 32|16@1+ (1,0) [0|0] ""  Kvaser,SteeringWheel
 SG_ Therm100 : 48|16@1+ (1,0) [0|0] ""  Kvaser,SteeringWheel

BO_ 225 Thermistor26: 8 ACULV
 SG_ Therm101 : 0|16@1+ (1,0) [0|0] ""  Kvaser,SteeringWheel
 SG_ Therm102 : 16|16@1+ (1,0) [0|0] ""  Kvaser,SteeringWheel
 SG_ Therm103 : 32|16@1+ (1,0) [0|0] ""  Kvaser,SteeringWheel
 SG_ Therm104 : 48|16@1+ (1,0) [0|0] ""  Kvaser,SteeringWheel

BO_ 226 Thermistor27: 8 ACULV
 SG_ Therm105 : 0|16@1+ (1,0) [0|0] ""  Kvaser,SteeringWheel
 SG_ Therm106 : 16|16@1+ (1,0) [0|0] ""  Kvaser,SteeringWheel
 SG_ Therm107 : 32|16@1+ (1,0) [0|0] ""  Kvaser,SteeringWheel
 SG_ Therm108 : 48|16@1+ (1,0) [0|0] ""  Kvaser,SteeringWheel

BO_ 227 Thermistor28: 8 ACULV
 SG_ Therm109 : 0|16@1+ (1,0) [0|0] ""  Kvaser,SteeringWheel
 SG_ Therm110 : 16|16@1+ (1,0) [0|0] ""  Kvaser,SteeringWheel
 SG_ Therm111 : 32|16@1+ (1,0) [0|0] ""  Kvaser,SteeringWheel
 SG_ Therm112 : 48|16@1+ (1,0) [0|0] ""  Kvaser,SteeringWheel

BO_ 228 Thermistor29: 8 ACULV
 SG_ Therm113 : 0|16@1+ (1,0) [0|0] ""  Kvaser,SteeringWheel
 SG_ Therm114 : 16|16@1+ (1,0) [0|0] ""  Kvaser,SteeringWheel
 SG_ Therm115 : 32|16@1+ (1,0) [0|0] ""  Kvaser,SteeringWheel
 SG_ Therm116 : 48|16@1+ (1,0) [0|0] ""  Kvaser,SteeringWheel

BO_ 229 Thermistor30: 8 ACULV
 SG_ Therm117 : 0|16@1+ (1,0) [0|0] ""  Kvaser,SteeringWheel
 SG_ Therm118 : 16|16@1+ (1,0) [0|0] ""  Kvaser,SteeringWheel
 SG_ Therm119 : 32|16@1+ (1,0) [0|0] ""  Kvaser,SteeringWheel
 SG_ Therm120 : 48|16@1+ (1,0) [0|0] ""  Kvaser,SteeringWheel

BO_ 230 Thermistor31: 8 ACULV
 SG_ Therm121 : 0|16@1+ (1,0) [0|0] ""  Kvaser,SteeringWheel
 SG_ Therm122 : 16|16@1+ (1,0) [0|0] ""  Kvaser,SteeringWheel
 SG_ Therm123 : 32|16@1+ (1,0) [0|0] ""  Kvaser,SteeringWheel
 SG_ Therm124 : 48|16@1+ (1,0) [0|0] ""  Kvaser,SteeringWheel

BO_ 231 Thermistor32: 8 ACULV
 SG_ Therm125 : 0|16@1+ (1,0) [0|0] ""  Kvaser,SteeringWheel
 SG_ Therm126 : 16|16@1+ (1,0) [0|0] ""  Kvaser,SteeringWheel
 SG_ Therm127 : 32|16@1+ (1,0) [0|0] ""  Kvaser,SteeringWheel
 SG_ Therm128 : 48|16@1+ (1,0) [0|0] ""  Kvaser,SteeringWheel

BO_ 232 Thermistor33: 8 ACULV
 SG_ Therm129 : 0|16@1+ (1,0) [0|0] ""  Kvaser,SteeringWheel
 SG_ Therm130 : 16|16@1+ (1,0) [0|0] ""  Kvaser,SteeringWheel
 SG_ Therm131 : 32|16@1+ (1,0) [0|0] ""  Kvaser,SteeringWheel
 SG_ Therm132 : 48|16@1+ (1,0) [0|0] ""  Kvaser,SteeringWheel

BO_ 233 Thermistor34: 8 ACULV
 SG_ Therm133 : 0|16@1+ (1,0) [0|0] ""  Kvaser,SteeringWheel
 SG_ Therm134 : 16|16@1+ (1,0) [0|0] ""  Kvaser,SteeringWheel
 SG_ Therm135 : 32|16@1+ (1,0) [0|0] ""  Kvaser,SteeringWheel
 SG_ Therm136 : 48|16@1+ (1,0) [0|0] ""  Kvaser,SteeringWheel

BO_ 234 Thermistor35: 8 ACULV
 SG_ Therm137 : 0|16@1+ (1,0) [0|0] ""  Kvaser,SteeringWheel
 SG_ Therm138 : 16|16@1+ (1,0) [0|0] ""  Kvaser,SteeringWheel
 SG_ Therm139 : 32|16@1+ (1,0) [0|0] ""  Kvaser,SteeringWheel
 SG_ Therm140 : 48|16@1+ (1,0) [0|0] ""  Kvaser,SteeringWheel

BO_ 235 Thermistor36: 8 ACULV
 SG_ Therm141 : 0|16@1+ (1,0) [0|0] ""  Kvaser,SteeringWheel
 SG_ Therm142 : 16|16@1+ (1,0) [0|0] ""  Kvaser,SteeringWheel
 SG_ Therm143 : 32|16@1+ (1,0) [0|0] ""  Kvaser,SteeringWheel
 SG_ Therm144 : 48|16@1+ (1,0) [0|0] ""  Kvaser,SteeringWheel

BO_ 236 Thermistor37: 8 ACULV
 SG_ Therm145 : 0|16@1+ (1,0) [0|0] ""  Kvaser,SteeringWheel
 SG_ Therm146 : 16|16@1+ (1,0) [0|0] ""  Kvaser,SteeringWheel
 SG_ Therm147 : 32|16@1+ (1,0) [0|0] ""  Kvaser,SteeringWheel
 SG_ Therm148 : 48|16@1+ (1,0) [0|0] ""  Kvaser,SteeringWheel

BO_ 237 Thermistor38: 8 ACULV
 SG_ Therm149 : 0|16@1+ (1,0) [0|0] ""  Kvaser,SteeringWheel
 SG_ Therm150 : 16|16@1+ (1,0) [0|0] ""  Kvaser,SteeringWheel
 SG_ Therm151 : 32|16@1+ (1,0) [0|0] ""  Kvaser,SteeringWheel
 SG_ Therm152 : 48|16@1+ (1,0) [0|0] ""  Kvaser,SteeringWheel

BO_ 238 Thermistor39: 8 ACULV
 SG_ Therm153 : 0|16@1+ (1,0) [0|0] ""  Kvaser,SteeringWheel
 SG_ Therm154 : 16|16@1+ (1,0) [0|0] ""  Kvaser,SteeringWheel
 SG_ Therm155 : 32|16@1+ (1,0) [0|0] ""  Kvaser,SteeringWheel
 SG_ Therm156 : 48|16@1+ (1,0) [0|0] ""  Kvaser,SteeringWheel

BO_ 239 Thermistor40: 8 ACULV
 SG_ Therm157 : 0|16@1+ (1,0) [0|0] ""  Kvaser,SteeringWheel
 SG_ Therm158 : 16|16@1+ (1,0) [0|0] ""  Kvaser,SteeringWheel
 SG_ Therm159 : 32|16@1+ (1,0) [0|0] ""  Kvaser,SteeringWheel
 SG_ Therm160 : 48|16@1+ (1,0) [0|0] ""  Kvaser,SteeringWheel

BO_ 240 Thermistor41: 8 ACULV
 SG_ Therm161 : 0|16@1+ (1,0) [0|0] ""  Kvaser,SteeringWheel
 SG_ Therm162 : 16|16@1+ (1,0) [0|0] ""  Kvaser,SteeringWheel
 SG_ Therm163 : 32|16@1+ (1,0) [0|0] ""  Kvaser,SteeringWheel
 SG_ Therm164 : 48|16@1+ (1,0) [0|0] ""  Kvaser,SteeringWheel

BO_ 241 Thermistor42: 8 ACULV
 SG_ Therm165 : 0|16@1+ (1,0) [0|0] ""  Kvaser,SteeringWheel
 SG_ Therm166 : 16|16@1+ (1,0) [0|0] ""  Kvaser,SteeringWheel
 SG_ Therm167 : 32|16@1+ (1,0) [0|0] ""  Kvaser,SteeringWheel
 SG_ Therm168 : 48|16@1+ (1,0) [0|0] ""  Kvaser,SteeringWheel

BO_ 242 Thermistor43: 8 ACULV
 SG_ Therm169 : 0|16@1+ (1,0) [0|0] ""  Kvaser,SteeringWheel
 SG_ Therm170 : 16|16@1+ (1,0) [0|0] ""  Kvaser,SteeringWheel
 SG_ Therm171 : 32|16@1+ (1,0) [0|0] ""  Kvaser,SteeringWheel
 SG_ Therm172 : 48|16@1+ (1,0) [0|0] ""  Kvaser,SteeringWheel

BO_ 243 Thermistor44: 8 ACULV
 SG_ Therm173 : 0|16@1+ (1,0) [0|0] ""  Kvaser,SteeringWheel
 SG_ Therm174 : 16|16@1+ (1,0) [0|0] ""  Kvaser,SteeringWheel
 SG_ Therm175 : 32|16@1+ (1,0) [0|0] ""  Kvaser,SteeringWheel
 SG_ Therm176 : 48|16@1+ (1,0) [0|0] ""  Kvaser,SteeringWheel

BO_ 244 Thermistor45: 8 ACULV
 SG_ Therm177 : 0|16@1+ (1,0) [0|0] ""  Kvaser,SteeringWheel
 SG_ Therm178 : 16|16@1+ (1,0) [0|0] ""  Kvaser,SteeringWheel
 SG_ Therm179 : 32|16@1+ (1,0) [0|0] ""  Kvaser,SteeringWheel
 SG_ Therm180 : 48|16@1+ (1,0) [0|0] ""  Kvaser,SteeringWheel

BO_ 245 Thermistor46: 8 ACULV
 SG_ Therm181 : 0|16@1+ (1,0) [0|0] ""  Kvaser,SteeringWheel
 SG_ Therm182 : 16|16@1+ (1,0) [0|0] ""  Kvaser,SteeringWheel
 SG_ Therm183 : 32|16@1+ (1,0) [0|0] ""  Kvaser,SteeringWheel
 SG_ Therm184 : 48|16@1+ (1,0) [0|0] ""  Kvaser,SteeringWheel

BO_ 246 Thermistor47: 8 ACULV
 SG_ Therm185 : 0|16@1+ (1,0) [0|0] ""  Kvaser,SteeringWheel
 SG_ Therm186 : 16|16@1+ (1,0) [0|0] ""  Kvaser,SteeringWheel
 SG_ Therm187 : 32|16@1+ (1,0) [0|0] ""  Kvaser,SteeringWheel
 SG_ Therm188 : 48|16@1+ (1,0) [0|0] ""  Kvaser,SteeringWheel

BO_ 247 Thermistor48: 8 ACULV
 SG_ Therm189 : 0|16@1+ (1,0) [0|0] ""  Kvaser,SteeringWheel
 SG_ Therm190 : 16|16@1+ (1,0) [0|0] ""  Kvaser,SteeringWheel
 SG_ Therm191 : 32|16@1+ (1,0) [0|0] ""  Kvaser,SteeringWheel
 SG_ Therm192 : 48|16@1+ (1,0) [0|0] ""  Kvaser,SteeringWheel

BO_ 248 Thermistor49: 8 ACULV
 SG_ Therm193 : 0|16@1+ (1,0) [0|0] ""  Kvaser,SteeringWheel
 SG_ Therm194 : 16|16@1+ (1,0) [0|0] ""  Kvaser,SteeringWheel
 SG_ Therm195 : 32|16@1+ (1,0) [0|0] ""  Kvaser,SteeringWheel
 SG_ Therm196 : 48|16@1+ (1,0) [0|0] ""  Kvaser,SteeringWheel

BO_ 5 PackVoltage: 4 ACULV
 SG_ PackVoltage : 0|32@1- (1,0) [0|0] ""  Kvaser,SteeringWheel

BO_ 6 TCU1: 7 TCU
 SG_ APPS1 : 0|16@1+ (1,0) [0|0] ""  Kvaser,SteeringWheel
 SG_ APPS2 : 16|16@1+ (1,0) [0|0] ""  Kvaser,SteeringWheel
 SG_ BSE : 32|16@1+ (1,0) [0|0] ""  Kvaser,SteeringWheel
 SG_ Status : 48|8@1+ (1,0) [0|0] ""  Kvaser,SteeringWheel

BO_ 8 ACULV_CAN2_1: 6 ACULV
 SG_ AMSStatus : 0|8@1+ (1,0) [0|0] ""  SteeringWheel,Kvaser
 SG_ FLD : 8|8@1+ (1,0) [0|0] ""  SteeringWheel,Kvaser
 SG_ StateOfCharge : 16|32@1- (1,0) [0|0] ""  SteeringWheel,Kvaser

BO_ 9 ACULV_CAN2_2: 8 ACULV
 SG_ AccumulatorVoltage : 0|32@1- (1,0) [0|0] ""  Kvaser,SteeringWheel
 SG_ TractiveVoltage : 32|32@1- (1,0) [0|0] ""  Kvaser,SteeringWheel

BO_ 10 ACULV_CAN2_3: 4 ACULV
 SG_ CellCurrent : 0|32@1- (1,0) [0|0] ""  Kvaser,SteeringWheel

BO_ 11 ACULV_CAN2_4: 5 ACULV
 SG_ IsolationMonitoring : 0|8@1+ (1,0) [0|0] ""  SteeringWheel,Kvaser
 SG_ IsolationMonitoring1 : 8|32@1- (1,0) [0|0] ""  SteeringWheel,Kvaser

BO_ 40 ACULV_CAN1_1: 8 ACULV
 SG_ ChargeStatus1 : 0|32@1- (1,0) [0|0] ""  Kvaser,SteeringWheel
 SG_ ChargeStatus2 : 32|32@1- (1,0) [0|0] ""  Kvaser,SteeringWheel

BO_ 41 ACULV_CAN1_2: 1 ACULV
 SG_ ChargeRequest : 0|8@1+ (1,0) [0|0] ""  SteeringWheel,Kvaser

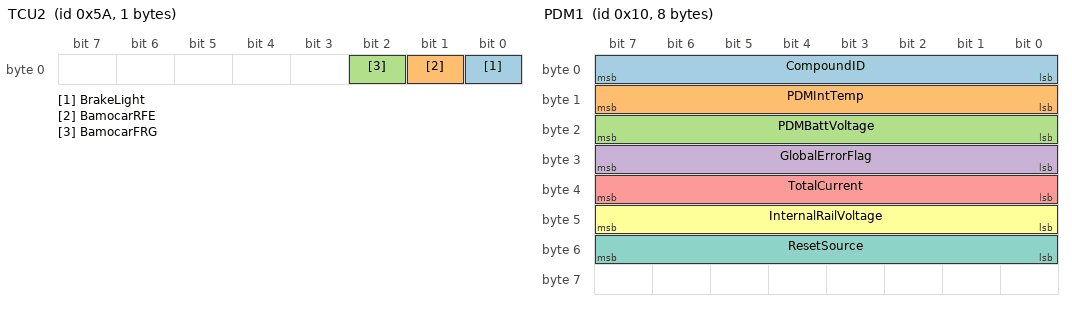
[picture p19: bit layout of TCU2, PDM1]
BO_ 90 TCU2: 1 TCU
 SG_ BrakeLight : 0|1@1+ (1,0) [0|0] ""  SteeringWheel,Kvaser
 SG_ BamocarRFE : 1|1@1+ (1,0) [0|0] ""  SteeringWheel,Kvaser
 SG_ BamocarFRG : 2|1@1+ (1,0) [0|0] ""  SteeringWheel,Kvaser

BO_ 20 FrontFrequency1: 8 FrontBoard
 SG_ Freq1 : 0|32@1- (1,0) [0|0] ""  Kvaser,SteeringWheel
 SG_ Freq2 : 32|32@1- (1,0) [0|0] ""  Kvaser,SteeringWheel

BO_ 21 FrontFrequency2: 8 FrontBoard
 SG_ Freq3 : 0|32@1- (1,0) [0|0] ""  Kvaser,SteeringWheel
 SG_ Freq4 : 32|32@1- (1,0) [0|0] ""  Kvaser,SteeringWheel

BO_ 385 BamocarTxData: 4 Bamocar
 SG_ REGID : 0|8@1+ (1,0) [0|0] ""  SteeringWheel,Kvaser
 SG_ Data : 8|24@1+ (1,0) [0|0] ""  SteeringWheel,Kvaser

BO_ 16 PDM1: 8 PDM
 SG_ CompoundID : 0|8@1+ (1,0) [0|0] ""  Kvaser,SteeringWheel
 SG_ PDMIntTemp : 8|8@1+ (1,0) [0|0] ""  Kvaser,SteeringWheel
 SG_ PDMBattVoltage : 16|8@1- (0.1216,0) [0|0] ""  Kvaser,SteeringWheel
 SG_ GlobalErrorFlag : 24|8@1+ (1,0) [0|0] ""  Kvaser,SteeringWheel
 SG_ TotalCurrent : 32|8@1+ (1,0) [0|0] ""  Kvaser,SteeringWheel
 SG_ InternalRailVoltage : 40|8@1- (0.0615,0) [0|0] ""  Kvaser,SteeringWheel
 SG_ ResetSource : 48|8@1+ (1,0) [0|0] ""  Kvaser,SteeringWheel

BO_ 60 IMURATEPVAS_week: 4 GPS
 SG_ GNSS_week : 0|32@1+ (1,0) [0|0] "" Vector__XXX

BO_ 61 IMURATEPVAS_seconds: 8 GPS
 SG_ GNSS_seconds : 0|64@1- (1,0) [0|0] "" Vector__XXX

BO_ 62 IMURATEPVAS_lat: 8 GPS
 SG_ latitude : 0|64@1- (1,0) [0|0] "" Vector__XXX

BO_ 63 IMURATEPVAS_long: 8 GPS
 SG_ longitude : 0|64@1- (1,0) [0|0] "" Vector__XXX

BO_ 64 IMURATEPVAS_height: 8 GPS
 SG_ height : 0|64@1- (1,0) [0|0] "" Vector__XXX

BO_ 65 IMURATEPVAS_nvel: 8 GPS
 SG_ north_velocity : 0|64@1- (1,0) [0|0] "" Vector__XXX

BO_ 66 IMURATEPVAS_evel: 8 GPS
 SG_ east_velocity : 0|64@1- (1,0) [0|0] "" Vector__XXX

BO_ 67 IMURATEPVAS_uvel: 8 GPS
 SG_ up_velocity : 0|64@1- (1,0) [0|0] "" Vector__XXX

BO_ 68 IMURATEPVAS_roll: 8 GPS
 SG_ roll : 0|64@1- (1,0) [0|0] "" Vector__XXX

BO_ 69 IMURATEPVAS_pitch: 8 GPS
 SG_ imu_pitch : 0|64@1- (1,0) [0|0] "" Vector__XXX

BO_ 70 IMURATEPVAS_azimuth: 8 GPS
 SG_ imu_azimuth : 0|64@1- (1,0) [0|0] "" Vector__XXX

BO_ 71 IMURATEPVAS_status: 1 GPS
 SG_ log_status : 0|8@1+ (1,0) [0|0] "" Vector__XXX

SIG_VALTYPE_ 5 PackVoltage : 1;
SIG_VALTYPE_ 8 StateOfCharge : 1;
SIG_VALTYPE_ 9 AccumulatorVoltage : 1;
SIG_VALTYPE_ 9 TractiveVoltage : 1;
SIG_VALTYPE_ 10 CellCurrent : 1;
SIG_VALTYPE_ 11 IsolationMonitoring1 : 1;
SIG_VALTYPE_ 40 ChargeStatus1 : 1;
SIG_VALTYPE_ 40 ChargeStatus2 : 1;
SIG_VALTYPE_ 20 Freq1 : 1;
SIG_VALTYPE_ 20 Freq2 : 1;
SIG_VALTYPE_ 21 Freq3 : 1;
SIG_VALTYPE_ 21 Freq4 : 1;
SIG_VALTYPE_ 16 PDMBattVoltage : 1;
SIG_VALTYPE_ 16 InternalRailVoltage : 1;
SIG_VALTYPE_ 61 GNSS_seconds : 2;
SIG_VALTYPE_ 62 latitude : 2;
SIG_VALTYPE_ 63 longitude : 2;
SIG_VALTYPE_ 64 height : 2;
SIG_VALTYPE_ 65 north_velocity : 2;
SIG_VALTYPE_ 66 east_velocity : 2;
SIG_VALTYPE_ 67 up_velocity : 2;
SIG_VALTYPE_ 68 roll : 2;
SIG_VALTYPE_ 69 imu_pitch : 2;
SIG_VALTYPE_ 70 imu_azimuth : 2;
